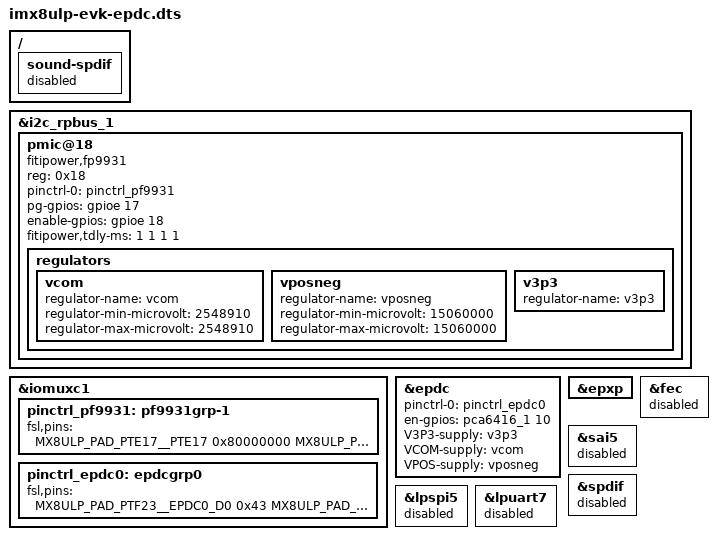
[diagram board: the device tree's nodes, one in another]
// SPDX-License-Identifier: GPL-2.0+
/*
 * Copyright 2021 NXP
 */

#include "imx8ulp-evk-rk055hdmipi4m.dts"

/ {
	sound-spdif {
		status = "disabled";
	};
};

&i2c_rpbus_1 {
	#address-cells = <1>;
	#size-cells = <0>;
	status = "okay";

	pmic@18 {
		compatible = "fitipower,fp9931";
		reg = <0x18>;
		pinctrl-names = "default";
		pinctrl-0 = <&pinctrl_pf9931>;
		pg-gpios = <&gpioe 17 GPIO_ACTIVE_HIGH>;
		enable-gpios = <&gpioe 18 GPIO_ACTIVE_HIGH>;
		fitipower,tdly-ms = <1 1 1 1>;

		regulators {
			vcom: vcom {
				regulator-name = "vcom";
				regulator-min-microvolt = <2548910>;
				regulator-max-microvolt = <2548910>;
			};

			vposneg: vposneg {
				regulator-name = "vposneg";
				regulator-min-microvolt = <15060000>;
				regulator-max-microvolt = <15060000>;
			};

			v3p3: v3p3 {
				regulator-name = "v3p3";
			};
		};
	};
};

&iomuxc1 {
	pinctrl_pf9931: pf9931grp-1 {
		fsl,pins = <
			MX8ULP_PAD_PTE17__PTE17		0x80000000  /* pwrgood */
			MX8ULP_PAD_PTE18__EPDC0_PWRWAKE		0x80000000  /* wakeup */
		>;
	};

	pinctrl_epdc0: epdcgrp0 {
		fsl,pins = <
			MX8ULP_PAD_PTF23__EPDC0_D0	0x43
			MX8ULP_PAD_PTF22__EPDC0_D1	0x43
			MX8ULP_PAD_PTF21__EPDC0_D2	0x43
			MX8ULP_PAD_PTF20__EPDC0_D3	0x43
			MX8ULP_PAD_PTF19__EPDC0_D4	0x43
			MX8ULP_PAD_PTF18__EPDC0_D5	0x43
			MX8ULP_PAD_PTF17__EPDC0_D6	0x43
			MX8ULP_PAD_PTF16__EPDC0_D7	0x43
			MX8ULP_PAD_PTF24__EPDC0_SDCLK	0x43
			MX8ULP_PAD_PTF25__EPDC0_GDSP	0x43
			MX8ULP_PAD_PTF26__EPDC0_SDLE	0x43
			MX8ULP_PAD_PTF27__EPDC0_SDCE0	0x43

			MX8ULP_PAD_PTF0__EPDC0_SDOE	0x43
			MX8ULP_PAD_PTE19__EPDC0_GDCLK	0x43
			MX8ULP_PAD_PTE20__EPDC0_GDOE	0x43
			MX8ULP_PAD_PTE21__EPDC0_GDRL	0x43

		>;
	};
};

&epdc {
	pinctrl-names = "default";
	pinctrl-0 = <&pinctrl_epdc0>;
	en-gpios = <&pca6416_1 10 GPIO_ACTIVE_HIGH>; /* switch */
	V3P3-supply = <&v3p3>;
	VCOM-supply = <&vcom>;
	VPOS-supply = <&vposneg>;
	status = "okay";
};

&epxp {
	status = "okay";
};

&fec {
	status = "disabled";
};

&sai5 {	/* conflict PAD_PTF23 */
	status = "disabled";
};

&spdif {/* conflict PAD_PTF25 */
	status = "disabled";
};

&lpspi5 {/* conflict PAD_PTF19 */
	status = "disabled";
};

&lpuart7 {/* conflict PAD_PTF23 */
	status = "disabled";
};
